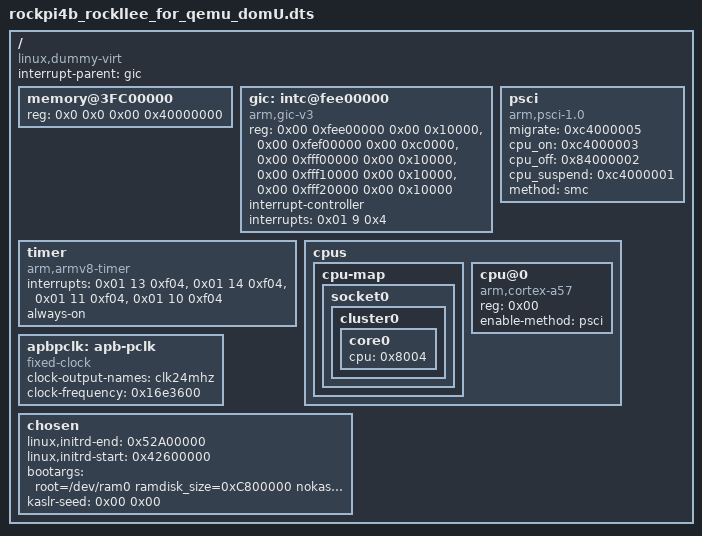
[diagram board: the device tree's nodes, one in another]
/dts-v1/;

/ {
	interrupt-parent = <&gic>; 
	#size-cells = <0x02>;
	#address-cells = <0x02>;
	compatible = "linux,dummy-virt";
	memory@3FC00000  {
		reg = <0x0   0x0   0x00 0x40000000>;
		device_type = "memory";
	};

	gic:intc@fee00000 {
		reg = <0x00 0xfee00000 0x00 0x10000>, /* GICD */
		      <0x00 0xfef00000 0x00 0xc0000>, /* GICR */
		      <0x00 0xfff00000 0x00 0x10000>, /* GICC */
		      <0x00 0xfff10000 0x00 0x10000>, /* GICH */
		      <0x00 0xfff20000 0x00 0x10000>; /* GICV */
		compatible = "arm,gic-v3";
		ranges;
		#size-cells = <0x02>;
		#address-cells = <0x02>;
		interrupt-controller;
		#interrupt-cells = <0x03>;
		interrupts = <0x01 9 0x4>;
	};                            

	timer {
		interrupts = <0x01 13 0xf04>, /* ARCH_TIMER_PHYS_SECURE_PPI ==> #interrupt-cells = <0x03> ==> !!! 0x10 is offset just !!! ==> 13为十进制 ==> hwirq = 13 + 16 = 29 */
					 <0x01 14 0xf04>, /* ARCH_TIMER_PHYS_NONSECURE_PPI */
					 <0x01 11 0xf04>, /* ARCH_TIMER_VIRT_PPI */
					 <0x01 10 0xf04>; /* ARCH_TIMER_HYP_PPI  */
		always-on;
		compatible = "arm,armv8-timer\0arm,armv7-timer";
	};

	psci {
		migrate = <0xc4000005>; /* PSCI function id  ==> 函数 psci_migrate */
		cpu_on = <0xc4000003>;  /* PSCI function id  ==> 函数 psci_cpu_on  */
		cpu_off = <0x84000002>; /* PSCI function id  ==> 函数 psci_cpu_off */
		cpu_suspend = <0xc4000001>; /* PSCI function id  ==> 函数 psci_cpu_suspend */
		method = "smc"; /* 在跑XEN的环境下，PSCI的方法要改为SMC，XEN才不会报错 */
		compatible = "arm,psci-1.0\0arm,psci-0.2\0arm,psci";
	};

	cpus {
		#size-cells = <0x00>;
		#address-cells = <0x01>;
		cpu-map {
			socket0 {
				cluster0 {
					core0 {
						cpu = <0x8004>;
					};
				};
			};
		};
		cpu@0 {
			phandle = <0x8004>;
			reg = <0x00>;
			enable-method = "psci";
			compatible = "arm,cortex-a57";
			device_type = "cpu";
		};
	};

	apbpclk:apb-pclk {
		phandle = <0x8000>;
		clock-output-names = "clk24mhz";
		clock-frequency = <0x16e3600>;
		#clock-cells = <0x00>;
		compatible = "fixed-clock";
	};

	chosen {
		linux,initrd-end = <0x52A00000>;
		linux,initrd-start = <0x42600000>;
		bootargs = "root=/dev/ram0  ramdisk_size=0xC800000  nokaslr earlycon=pl011,0xf6ff0000  console=ttyS0,1500000n8 loglevel=8 rw ";
		kaslr-seed = <0x00 0x00>;
	};
};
